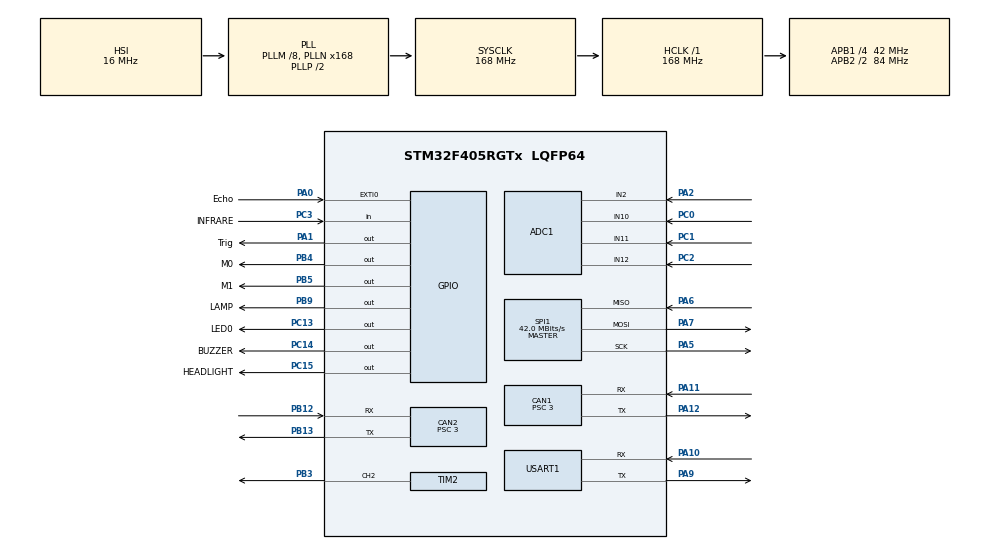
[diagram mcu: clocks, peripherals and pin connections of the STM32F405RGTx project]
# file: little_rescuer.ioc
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PC13-ANTI_TAMP.GPIO_Speed=GPIO_SPEED_FREQ_LOW
Mcu.Family=STM32F4
VP_TIM5_VS_ClockSourceINT.Mode=Internal
CAN1.NART=ENABLE
PA6.Mode=Full_Duplex_Master
PH0-OSC_IN.Signal=RCC_OSC_IN
RCC.CortexFreq_Value=168000000
SPI1.VirtualType=VM_MASTER
ADC1.ContinuousConvMode=ENABLE
CAN2.CalculateTimeBit=999.99
SH.ADCx_IN2.0=ADC1_IN2,IN2
VP_IWDG_VS_IWDG.Mode=IWDG_Activate
PA11.Mode=CAN_Activate
TIM2.Channel-PWM\ Generation2\ CH2=TIM_CHANNEL_2
PB13.Signal=CAN2_TX
PC15-OSC32_OUT.GPIO_Label=HEADLIGHT
RCC.SYSCLKSource=RCC_SYSCLKSOURCE_PLLCLK
ProjectManager.StackSize=0x400
VP_TIM7_VS_ClockSourceINT.Mode=Enable_Timer
PA12.Signal=CAN1_TX
NVIC.TIM5_IRQn=true\:4\:0\:true\:false\:true\:true\:true
ADC1.Channel-3\#ChannelRegularConversion=ADC_CHANNEL_12
SPI1.Direction=SPI_DIRECTION_2LINES
RCC.HCLKFreq_Value=168000000
RCC.APB2TimFreq_Value=168000000
TIM3.Period=15
Dma.ADC1.0.Direction=DMA_PERIPH_TO_MEMORY
ADC1.Channel-2\#ChannelRegularConversion=ADC_CHANNEL_11
PB5.PinState=GPIO_PIN_RESET
SPI1.CalculateBaudRate=42.0 MBits/s
PC3.Signal=GPIO_Input
TIM7.Period=99
NVIC.DMA2_Stream0_IRQn=true\:2\:0\:true\:false\:true\:false\:true
Dma.ADC1.0.MemDataAlignment=DMA_MDATAALIGN_HALFWORD
RCC.AHBFreq_Value=168000000
PH0-OSC_IN.Mode=HSE-External-Oscillator
RCC.HSE_VALUE=8000000
ADC1.ScanConvMode=ENABLE
PC13-ANTI_TAMP.Signal=GPIO_Output
ADC1.SamplingTime-4\#ChannelRegularConversion=ADC_SAMPLETIME_480CYCLES
ADC1.Rank-2\#ChannelRegularConversion=2
PA14.Mode=Serial_Wire
CAN2.Prescaler=3
TIM3.Prescaler=20999
Dma.ADC1.0.PeriphInc=DMA_PINC_DISABLE
TIM4.Period=0xffff
PH1-OSC_OUT.Mode=HSE-External-Oscillator
CAN1.Prescaler=3
Mcu.Package=LQFP64
PB9.Signal=GPIO_Output
TIM2.Prescaler=8399
PA6.Signal=SPI1_MISO
PB12.Mode=CAN_Activate
CAN2.BS1=CAN_BS1_7TQ
CAN2.BS2=CAN_BS2_6TQ
IWDG.Reload=100
PA10.Signal=USART1_RX
PB9.GPIO_PuPd=GPIO_PULLUP
TIM7.AutoReloadPreload=TIM_AUTORELOAD_PRELOAD_ENABLE
TIM2.Pulse-PWM\ Generation2\ CH2=1750
PB5.GPIO_Speed=GPIO_SPEED_FREQ_HIGH
RCC.APB2CLKDivider=RCC_HCLK_DIV2
PB9.GPIO_Speed=GPIO_SPEED_FREQ_HIGH
PB5.GPIO_Label=M1
RCC.APB1TimFreq_Value=84000000
Dma.ADC1.0.FIFOMode=DMA_FIFOMODE_DISABLE
PC14-OSC32_IN.GPIO_Label=BUZZER
PB13.Mode=CAN_Activate
NVIC.USART1_IRQn=true\:7\:0\:true\:false\:true\:true\:true
Dma.Request0=ADC1
SPI1.BaudRatePrescaler=SPI_BAUDRATEPRESCALER_2
CAN1.CalculateTimeBit=999.99
NVIC.TIM7_IRQn=true\:6\:0\:true\:false\:true\:true\:true
VP_TIM3_VS_ClockSourceINT.Mode=Internal
ADC1.Rank-4\#ChannelRegularConversion=4
PB4.Signal=GPIO_Output
CAN1.CalculateTimeQuantum=71.42857142857143
PA5.Mode=Full_Duplex_Master
CAN2.CalculateBaudRate=1000000
TIM4.AutoReloadPreload=TIM_AUTORELOAD_PRELOAD_ENABLE
Dma.ADC1.0.Instance=DMA2_Stream0
PA7.Mode=Full_Duplex_Master
PB9.GPIO_Label=LAMP
ADC1.Channel-4\#ChannelRegularConversion=ADC_CHANNEL_2
PA10.Mode=Asynchronous
PC13-ANTI_TAMP.GPIO_PuPd=GPIO_PULLDOWN
TIM3.AutoReloadPreload=TIM_AUTORELOAD_PRELOAD_ENABLE
PC13-ANTI_TAMP.GPIO_Label=LED0
CAN2.NART=ENABLE
CAN1.CalculateBaudRate=1000000
PC2.Signal=ADCx_IN12
ADC1.DiscontinuousConvMode=DISABLE
PC0.Signal=ADCx_IN10
RCC.APB1CLKDivider=RCC_HCLK_DIV4
PC14-OSC32_IN.Signal=GPIO_Output
NVIC.CAN2_RX1_IRQn=true\:2\:0\:true\:false\:true\:true\:true
PA0-WKUP.GPIO_ModeDefaultEXTI=GPIO_MODE_IT_RISING_FALLING
ADC1.SamplingTime-2\#ChannelRegularConversion=ADC_SAMPLETIME_480CYCLES
PC13-ANTI_TAMP.PinState=GPIO_PIN_RESET
TIM5.AutoReloadPreload=TIM_AUTORELOAD_PRELOAD_ENABLE
PA0-WKUP.GPIO_Label=Echo
PA0-WKUP.Signal=GPXTI0
PA13.Signal=SYS_JTMS-SWDIO
SH.S_TIM2_CH2.0=TIM2_CH2,PWM Generation2 CH2
Dma.ADC1.0.PeriphDataAlignment=DMA_PDATAALIGN_HALFWORD
PA9.Mode=Asynchronous
SH.ADCx_IN12.0=ADC1_IN12,IN12
CAN1.BS2=CAN_BS2_6TQ
CAN1.BS1=CAN_BS1_7TQ
ProjectManager.TargetToolchain=STM32CubeIDE
Dma.ADC1.0.Mode=DMA_CIRCULAR
Dma.ADC1.0.Priority=DMA_PRIORITY_LOW
PA9.Signal=USART1_TX
ADC1.Channel-1\#ChannelRegularConversion=ADC_CHANNEL_10
PB4.GPIO_PuPd=GPIO_PULLDOWN
TIM4.Prescaler=167
RCC.LSE_VALUE=32768
PC15-OSC32_OUT.Signal=GPIO_Output
PA1.Signal=GPIO_Output
PA5.Signal=SPI1_SCK
TIM7.Prescaler=5599
board=custom
RCC.VCOOutputFreq_Value=336000000
NVIC.TIM3_IRQn=true\:3\:0\:true\:false\:true\:true\:true
PB4.GPIO_Speed=GPIO_SPEED_FREQ_HIGH
RCC.APB2Freq_Value=84000000
SPI1.CRCCalculation=SPI_CRCCALCULATION_DISABLE
SH.ADCx_IN11.0=ADC1_IN11,IN11
TIM2.OCMode_PWM-PWM\ Generation2\ CH2=TIM_OCMODE_PWM2
PB4.GPIO_Label=M0
VP_TIM2_VS_ClockSourceINT.Mode=Internal
SPI1.Mode=SPI_MODE_MASTER
PA1.GPIO_Speed=GPIO_SPEED_FREQ_VERY_HIGH
PA1.GPIO_Label=Trig
CAN2.CalculateTimeQuantum=71.42857142857143
PH1-OSC_OUT.Signal=RCC_OSC_OUT
PC15-OSC32_OUT.GPIO_PuPd=GPIO_PULLUP
ADC1.DMAContinuousRequests=ENABLE
TIM2.Period=1999
ADC1.NbrOfConversion=4
PA13.Mode=Serial_Wire
Mcu.Name=STM32F405RGTx
PA2.Signal=ADCx_IN2
RCC.48MHZClocksFreq_Value=84000000
PB3.Signal=S_TIM2_CH2
NVIC.EXTI0_IRQn=true\:4\:0\:true\:false\:true\:true\:true
ADC1.SamplingTime-1\#ChannelRegularConversion=ADC_SAMPLETIME_480CYCLES
RCC.SYSCLKFreq_VALUE=168000000
PB5.Signal=GPIO_Output
ADC1.master=1
PA12.Mode=CAN_Activate
ADC1.Rank-3\#ChannelRegularConversion=3
ADC1.SamplingTime-3\#ChannelRegularConversion=ADC_SAMPLETIME_480CYCLES
TIM5.Prescaler=8399
PB5.GPIO_PuPd=GPIO_PULLDOWN
USART1.VirtualMode=VM_ASYNC
ADC1.Rank-1\#ChannelRegularConversion=1
PA11.Signal=CAN1_RX
PA14.Signal=SYS_JTCK-SWCLK
Dma.ADC1.0.MemInc=DMA_MINC_ENABLE
SH.ADCx_IN10.0=ADC1_IN10,IN10
ProjectManager.HeapSize=0x200
RCC.HSI_VALUE=16000000
VP_TIM4_VS_ClockSourceINT.Mode=Internal
NVIC.PriorityGroup=NVIC_PRIORITYGROUP_3
ADC1.NbrOfConversionFlag=1
RCC.PLLM=8
RCC.PLLN=168
TIM2.AutoReloadPreload=TIM_AUTORELOAD_PRELOAD_DISABLE
PC3.GPIO_Label=INFRARE
PA0-WKUP.GPIO_PuPd=GPIO_PULLDOWN
TIM5.Period=999
PC14-OSC32_IN.GPIO_PuPd=GPIO_PULLUP
RCC.APB1Freq_Value=42000000
PC1.Signal=ADCx_IN11
PB12.Signal=CAN2_RX
NVIC.CAN1_RX0_IRQn=true\:1\:0\:true\:false\:true\:true\:true
PC3.GPIO_PuPd=GPIO_PULLDOWN
PA7.Signal=SPI1_MOSI

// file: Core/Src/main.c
/* USER CODE BEGIN Header */
/**
 ******************************************************************************
 * @file           : main.c
 * @brief          : Main program body
 ******************************************************************************
 * @attention
 *
 * <h2><center>&copy; Copyright (c) 2021 STMicroelectronics.
 * All rights reserved.</center></h2>
 *
 * This software component is licensed by ST under BSD 3-Clause license,
 * the "License"; You may not use this file except in compliance with the
 * License. You may obtain a copy of the License at:
 *                        opensource.org/licenses/BSD-3-Clause
 *
 ******************************************************************************
 */
/* USER CODE END Header */
#include "main.h"
#include "adc.h"
#include "can.h"
#include "dma.h"
#include "iwdg.h"
#include "spi.h"
#include "tim.h"
#include "usart.h"
#include "gpio.h"

void SystemClock_Config(void);

int main(void)
{

  /* MCU Configuration--------------------------------------------------------*/

  /* Reset of all peripherals, Initializes the Flash interface and the Systick. */
  HAL_Init();

  /* Configure the system clock */
  SystemClock_Config();

  /* Initialize all configured peripherals */
  MX_GPIO_Init();
  MX_DMA_Init();
  MX_ADC1_Init();
  MX_CAN1_Init();
  MX_CAN2_Init();
  MX_SPI1_Init();
  MX_TIM2_Init();
  MX_TIM3_Init();
  MX_TIM4_Init();
  MX_TIM5_Init();
  MX_TIM7_Init();
  MX_USART1_UART_Init();
  MX_IWDG_Init();

  /* Infinite loop */
  /* USER CODE BEGIN WHILE */
  Control_Initialize();
  printf("start\r\n");
	while (1)
	{
		if (refresh == 1)
		{
			refresh = 0;
		}
		HAL_IWDG_Refresh(&hiwdg);   //���Ź�ι��

		debug();
    /* USER CODE END WHILE */

	}
}

void SystemClock_Config(void)
{
  RCC_OscInitTypeDef RCC_OscInitStruct = {0};
  RCC_ClkInitTypeDef RCC_ClkInitStruct = {0};

  /** Configure the main internal regulator output voltage
  */
  __HAL_RCC_PWR_CLK_ENABLE();
  __HAL_PWR_VOLTAGESCALING_CONFIG(PWR_REGULATOR_VOLTAGE_SCALE1);
  /** Initializes the RCC Oscillators according to the specified parameters
  * in the RCC_OscInitTypeDef structure.
  */
  RCC_OscInitStruct.OscillatorType = RCC_OSCILLATORTYPE_HSI|RCC_OSCILLATORTYPE_LSI;
  RCC_OscInitStruct.HSIState = RCC_HSI_ON;
  RCC_OscInitStruct.HSICalibrationValue = RCC_HSICALIBRATION_DEFAULT;
  RCC_OscInitStruct.LSIState = RCC_LSI_ON;
  RCC_OscInitStruct.PLL.PLLState = RCC_PLL_ON;
  RCC_OscInitStruct.PLL.PLLSource = RCC_PLLSOURCE_HSI;
  RCC_OscInitStruct.PLL.PLLM = 8;
  RCC_OscInitStruct.PLL.PLLN = 168;
  RCC_OscInitStruct.PLL.PLLP = RCC_PLLP_DIV2;
  RCC_OscInitStruct.PLL.PLLQ = 4;
  if (HAL_RCC_OscConfig(&RCC_OscInitStruct) != HAL_OK)
  {
    Error_Handler();
  }
  /** Initializes the CPU, AHB and APB buses clocks
  */
  RCC_ClkInitStruct.ClockType = RCC_CLOCKTYPE_HCLK|RCC_CLOCKTYPE_SYSCLK
                              |RCC_CLOCKTYPE_PCLK1|RCC_CLOCKTYPE_PCLK2;
  RCC_ClkInitStruct.SYSCLKSource = RCC_SYSCLKSOURCE_PLLCLK;
  RCC_ClkInitStruct.AHBCLKDivider = RCC_SYSCLK_DIV1;
  RCC_ClkInitStruct.APB1CLKDivider = RCC_HCLK_DIV4;
  RCC_ClkInitStruct.APB2CLKDivider = RCC_HCLK_DIV2;

  if (HAL_RCC_ClockConfig(&RCC_ClkInitStruct, FLASH_LATENCY_5) != HAL_OK)
  {
    Error_Handler();
  }
}

void Error_Handler(void)
{
  /* USER CODE BEGIN Error_Handler_Debug */
	/* User can add his own implementation to report the HAL error return state */
	__disable_irq();
//  while (1)
//  {
//  }
	printf("ERROR\r\n");
  /* USER CODE END Error_Handler_Debug */
}

/************************ (C) COPYRIGHT STMicroelectronics *****END OF FILE****/
